VERSION "10.8"

NS_ :

BS_:

BU_:
VAL_TABLE_ Value_Table_Track_Status 7 "New Coasting Target" 6 "Invalid Coasting Target" 5 "Merged Target" 4 "Coasting Target" 3 "Updated Target" 2 "New Updated Target" 1 "New Target" 0 "No Target" ;

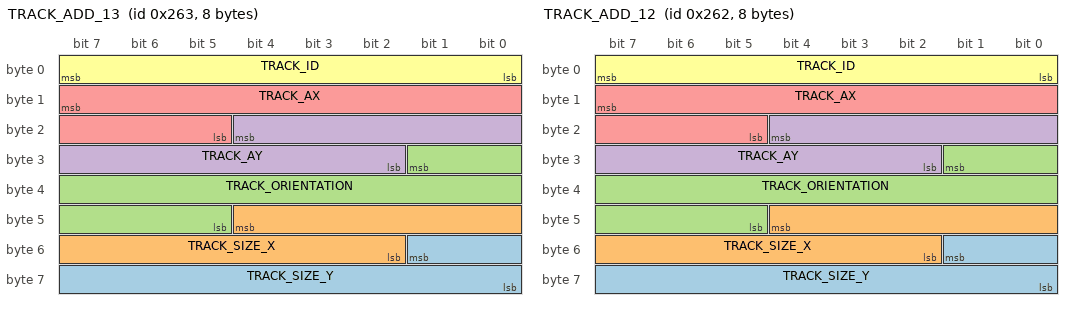
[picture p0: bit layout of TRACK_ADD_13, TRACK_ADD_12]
BO_ 611 TRACK_ADD_13: 8 Vector__XXX
 SG_ TRACK_SIZE_Y : 49|10@0+ (0.01,0) [0|10.23] "m" Vector__XXX
 SG_ TRACK_SIZE_X : 44|11@0+ (0.01,0) [0|20.47] "m" Vector__XXX
 SG_ TRACK_ORIENTATION : 25|13@0- (0.002,0) [-8.192|8.19] "rad" Vector__XXX
 SG_ TRACK_AY : 20|11@0- (0.01,0) [-10.24|10.23] "m/s^2" Vector__XXX
 SG_ TRACK_AX : 15|11@0- (0.01,0) [-10.24|10.23] "m/s^2" Vector__XXX
 SG_ TRACK_ID : 7|8@0+ (1,0) [0|255] "" Vector__XXX

BO_ 610 TRACK_ADD_12: 8 Vector__XXX
 SG_ TRACK_SIZE_Y : 49|10@0+ (0.01,0) [0|10.23] "m" Vector__XXX
 SG_ TRACK_SIZE_X : 44|11@0+ (0.01,0) [0|20.47] "m" Vector__XXX
 SG_ TRACK_ORIENTATION : 25|13@0- (0.002,0) [-8.192|8.19] "rad" Vector__XXX
 SG_ TRACK_AY : 20|11@0- (0.01,0) [-10.24|10.23] "m/s^2" Vector__XXX
 SG_ TRACK_AX : 15|11@0- (0.01,0) [-10.24|10.23] "m/s^2" Vector__XXX
 SG_ TRACK_ID : 7|8@0+ (1,0) [0|255] "" Vector__XXX

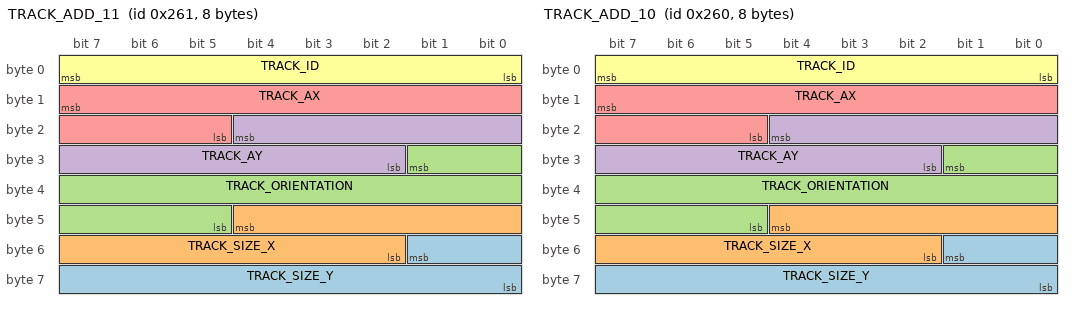
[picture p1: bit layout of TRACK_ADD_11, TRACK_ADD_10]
BO_ 609 TRACK_ADD_11: 8 Vector__XXX
 SG_ TRACK_SIZE_Y : 49|10@0+ (0.01,0) [0|10.23] "m" Vector__XXX
 SG_ TRACK_SIZE_X : 44|11@0+ (0.01,0) [0|20.47] "m" Vector__XXX
 SG_ TRACK_ORIENTATION : 25|13@0- (0.002,0) [-8.192|8.19] "rad" Vector__XXX
 SG_ TRACK_AY : 20|11@0- (0.01,0) [-10.24|10.23] "m/s^2" Vector__XXX
 SG_ TRACK_AX : 15|11@0- (0.01,0) [-10.24|10.23] "m/s^2" Vector__XXX
 SG_ TRACK_ID : 7|8@0+ (1,0) [0|255] "" Vector__XXX

BO_ 608 TRACK_ADD_10: 8 Vector__XXX
 SG_ TRACK_SIZE_Y : 49|10@0+ (0.01,0) [0|10.23] "m" Vector__XXX
 SG_ TRACK_SIZE_X : 44|11@0+ (0.01,0) [0|20.47] "m" Vector__XXX
 SG_ TRACK_ORIENTATION : 25|13@0- (0.002,0) [-8.192|8.19] "rad" Vector__XXX
 SG_ TRACK_AY : 20|11@0- (0.01,0) [-10.24|10.23] "m/s^2" Vector__XXX
 SG_ TRACK_AX : 15|11@0- (0.01,0) [-10.24|10.23] "m/s^2" Vector__XXX
 SG_ TRACK_ID : 7|8@0+ (1,0) [0|255] "" Vector__XXX

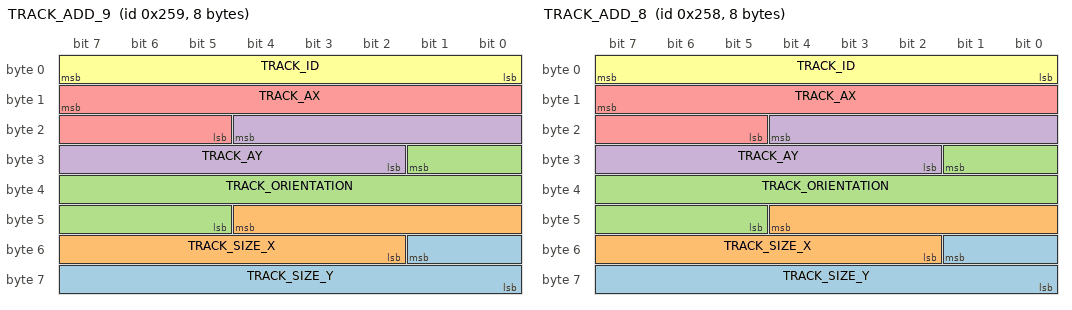
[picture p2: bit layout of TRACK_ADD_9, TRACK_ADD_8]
BO_ 601 TRACK_ADD_9: 8 Vector__XXX
 SG_ TRACK_SIZE_Y : 49|10@0+ (0.01,0) [0|10.23] "m" Vector__XXX
 SG_ TRACK_SIZE_X : 44|11@0+ (0.01,0) [0|20.47] "m" Vector__XXX
 SG_ TRACK_ORIENTATION : 25|13@0- (0.002,0) [-8.192|8.19] "rad" Vector__XXX
 SG_ TRACK_AY : 20|11@0- (0.01,0) [-10.24|10.23] "m/s^2" Vector__XXX
 SG_ TRACK_AX : 15|11@0- (0.01,0) [-10.24|10.23] "m/s^2" Vector__XXX
 SG_ TRACK_ID : 7|8@0+ (1,0) [0|255] "" Vector__XXX

BO_ 600 TRACK_ADD_8: 8 Vector__XXX
 SG_ TRACK_SIZE_Y : 49|10@0+ (0.01,0) [0|10.23] "m" Vector__XXX
 SG_ TRACK_SIZE_X : 44|11@0+ (0.01,0) [0|20.47] "m" Vector__XXX
 SG_ TRACK_ORIENTATION : 25|13@0- (0.002,0) [-8.192|8.19] "rad" Vector__XXX
 SG_ TRACK_AY : 20|11@0- (0.01,0) [-10.24|10.23] "m/s^2" Vector__XXX
 SG_ TRACK_AX : 15|11@0- (0.01,0) [-10.24|10.23] "m/s^2" Vector__XXX
 SG_ TRACK_ID : 7|8@0+ (1,0) [0|255] "" Vector__XXX

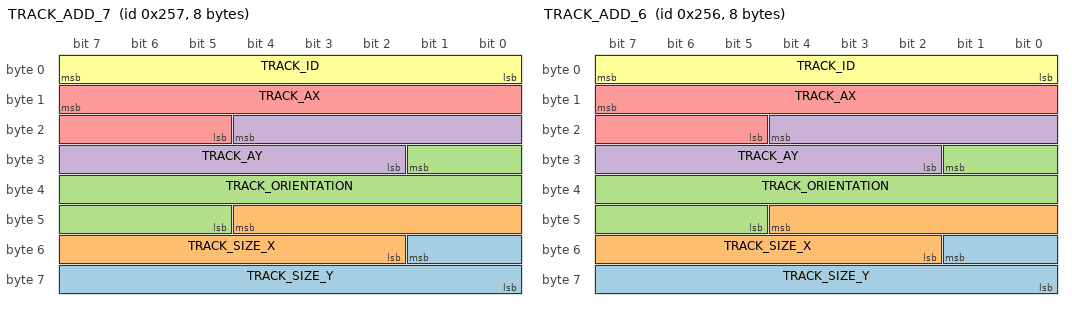
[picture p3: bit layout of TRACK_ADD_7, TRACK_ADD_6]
BO_ 599 TRACK_ADD_7: 8 Vector__XXX
 SG_ TRACK_SIZE_Y : 49|10@0+ (0.01,0) [0|10.23] "m" Vector__XXX
 SG_ TRACK_SIZE_X : 44|11@0+ (0.01,0) [0|20.47] "m" Vector__XXX
 SG_ TRACK_ORIENTATION : 25|13@0- (0.002,0) [-8.192|8.19] "rad" Vector__XXX
 SG_ TRACK_AY : 20|11@0- (0.01,0) [-10.24|10.23] "m/s^2" Vector__XXX
 SG_ TRACK_AX : 15|11@0- (0.01,0) [-10.24|10.23] "m/s^2" Vector__XXX
 SG_ TRACK_ID : 7|8@0+ (1,0) [0|255] "" Vector__XXX

BO_ 598 TRACK_ADD_6: 8 Vector__XXX
 SG_ TRACK_SIZE_Y : 49|10@0+ (0.01,0) [0|10.23] "m" Vector__XXX
 SG_ TRACK_SIZE_X : 44|11@0+ (0.01,0) [0|20.47] "m" Vector__XXX
 SG_ TRACK_ORIENTATION : 25|13@0- (0.002,0) [-8.192|8.19] "rad" Vector__XXX
 SG_ TRACK_AY : 20|11@0- (0.01,0) [-10.24|10.23] "m/s^2" Vector__XXX
 SG_ TRACK_AX : 15|11@0- (0.01,0) [-10.24|10.23] "m/s^2" Vector__XXX
 SG_ TRACK_ID : 7|8@0+ (1,0) [0|255] "" Vector__XXX

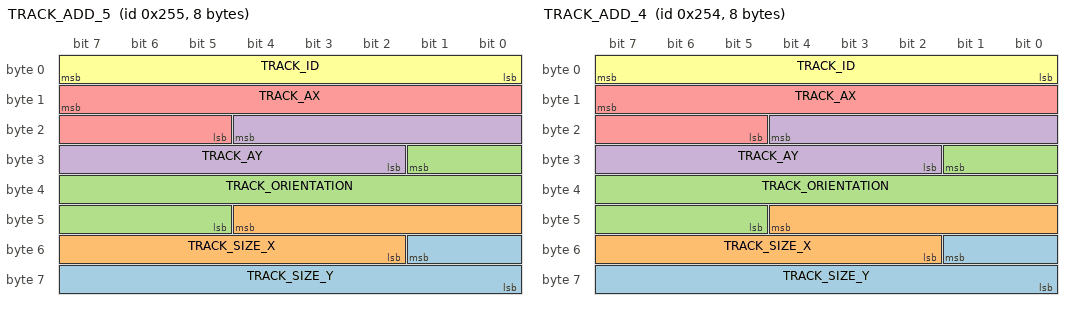
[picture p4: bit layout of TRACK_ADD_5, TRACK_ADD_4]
BO_ 597 TRACK_ADD_5: 8 Vector__XXX
 SG_ TRACK_SIZE_Y : 49|10@0+ (0.01,0) [0|10.23] "m" Vector__XXX
 SG_ TRACK_SIZE_X : 44|11@0+ (0.01,0) [0|20.47] "m" Vector__XXX
 SG_ TRACK_ORIENTATION : 25|13@0- (0.002,0) [-8.192|8.19] "rad" Vector__XXX
 SG_ TRACK_AY : 20|11@0- (0.01,0) [-10.24|10.23] "m/s^2" Vector__XXX
 SG_ TRACK_AX : 15|11@0- (0.01,0) [-10.24|10.23] "m/s^2" Vector__XXX
 SG_ TRACK_ID : 7|8@0+ (1,0) [0|255] "" Vector__XXX

BO_ 596 TRACK_ADD_4: 8 Vector__XXX
 SG_ TRACK_SIZE_Y : 49|10@0+ (0.01,0) [0|10.23] "m" Vector__XXX
 SG_ TRACK_SIZE_X : 44|11@0+ (0.01,0) [0|20.47] "m" Vector__XXX
 SG_ TRACK_ORIENTATION : 25|13@0- (0.002,0) [-8.192|8.19] "rad" Vector__XXX
 SG_ TRACK_AY : 20|11@0- (0.01,0) [-10.24|10.23] "m/s^2" Vector__XXX
 SG_ TRACK_AX : 15|11@0- (0.01,0) [-10.24|10.23] "m/s^2" Vector__XXX
 SG_ TRACK_ID : 7|8@0+ (1,0) [0|255] "" Vector__XXX

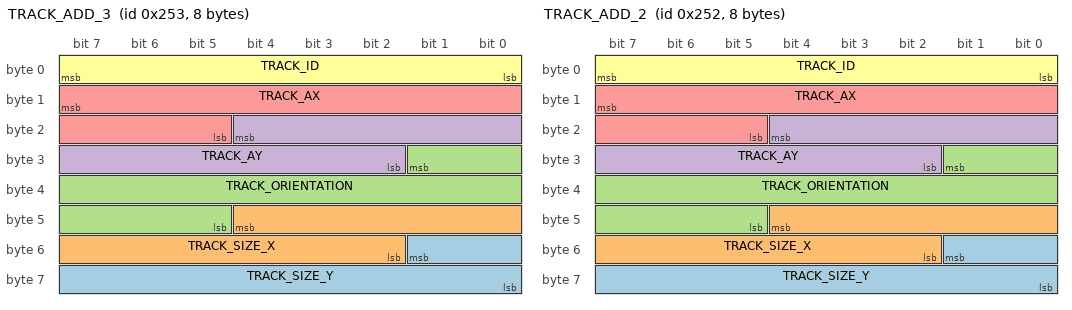
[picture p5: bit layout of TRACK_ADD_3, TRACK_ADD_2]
BO_ 595 TRACK_ADD_3: 8 Vector__XXX
 SG_ TRACK_SIZE_Y : 49|10@0+ (0.01,0) [0|10.23] "m" Vector__XXX
 SG_ TRACK_SIZE_X : 44|11@0+ (0.01,0) [0|20.47] "m" Vector__XXX
 SG_ TRACK_ORIENTATION : 25|13@0- (0.002,0) [-8.192|8.19] "rad" Vector__XXX
 SG_ TRACK_AY : 20|11@0- (0.01,0) [-10.24|10.23] "m/s^2" Vector__XXX
 SG_ TRACK_AX : 15|11@0- (0.01,0) [-10.24|10.23] "m/s^2" Vector__XXX
 SG_ TRACK_ID : 7|8@0+ (1,0) [0|255] "" Vector__XXX

BO_ 594 TRACK_ADD_2: 8 Vector__XXX
 SG_ TRACK_SIZE_Y : 49|10@0+ (0.01,0) [0|10.23] "m" Vector__XXX
 SG_ TRACK_SIZE_X : 44|11@0+ (0.01,0) [0|20.47] "m" Vector__XXX
 SG_ TRACK_ORIENTATION : 25|13@0- (0.002,0) [-8.192|8.19] "rad" Vector__XXX
 SG_ TRACK_AY : 20|11@0- (0.01,0) [-10.24|10.23] "m/s^2" Vector__XXX
 SG_ TRACK_AX : 15|11@0- (0.01,0) [-10.24|10.23] "m/s^2" Vector__XXX
 SG_ TRACK_ID : 7|8@0+ (1,0) [0|255] "" Vector__XXX

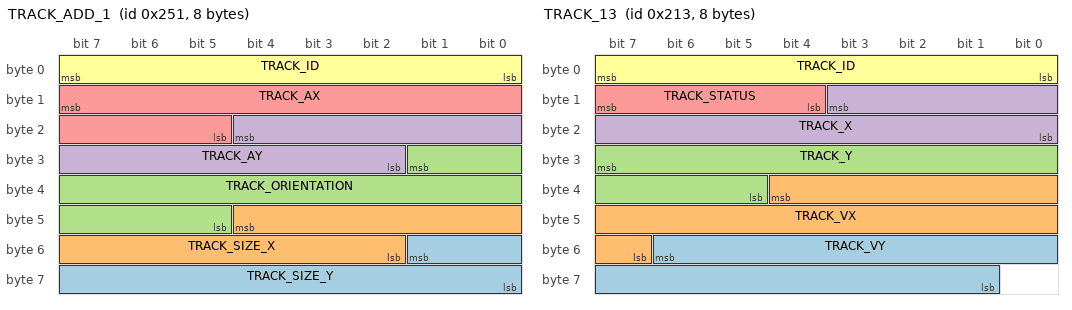
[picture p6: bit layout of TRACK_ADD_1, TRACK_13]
BO_ 593 TRACK_ADD_1: 8 Vector__XXX
 SG_ TRACK_SIZE_Y : 49|10@0+ (0.01,0) [0|10.23] "m" Vector__XXX
 SG_ TRACK_SIZE_X : 44|11@0+ (0.01,0) [0|20.47] "m" Vector__XXX
 SG_ TRACK_ORIENTATION : 25|13@0- (0.002,0) [-8.192|8.19] "rad" Vector__XXX
 SG_ TRACK_AY : 20|11@0- (0.01,0) [-10.24|10.23] "m/s^2" Vector__XXX
 SG_ TRACK_AX : 15|11@0- (0.01,0) [-10.24|10.23] "m/s^2" Vector__XXX
 SG_ TRACK_ID : 7|8@0+ (1,0) [0|255] "" Vector__XXX

BO_ 531 TRACK_13: 8 Vector__XXX
 SG_ TRACK_VY : 54|14@0- (0.01,0) [-81.92|81.91] "m/s" Vector__XXX
 SG_ TRACK_VX : 36|14@0- (0.01,0) [-81.92|81.91] "m/s" Vector__XXX
 SG_ TRACK_Y : 31|11@0- (0.04,0) [-40.9|40.9] "m" Vector__XXX
 SG_ TRACK_X : 11|12@0- (0.1,0) [-204.8|204.7] "m" Vector__XXX
 SG_ TRACK_STATUS : 15|4@0+ (1,0) [0|0] "" Vector__XXX
 SG_ TRACK_ID : 7|8@0+ (1,0) [0|255] "" Vector__XXX

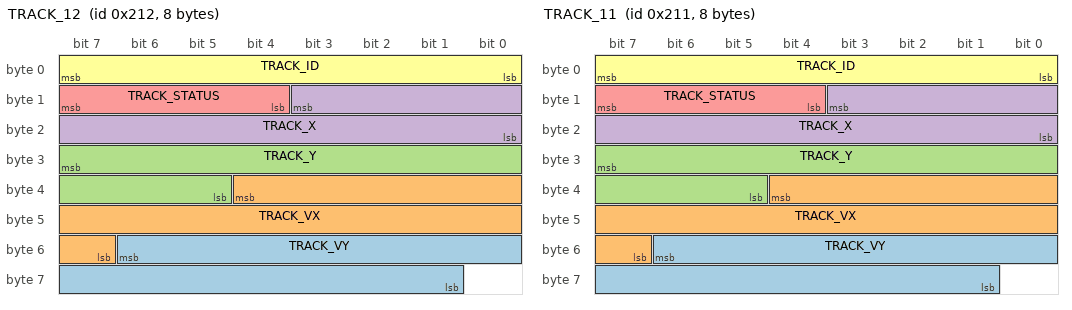
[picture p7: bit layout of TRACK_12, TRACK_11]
BO_ 530 TRACK_12: 8 Vector__XXX
 SG_ TRACK_VY : 54|14@0- (0.01,0) [-81.92|81.91] "m/s" Vector__XXX
 SG_ TRACK_VX : 36|14@0- (0.01,0) [-81.92|81.91] "m/s" Vector__XXX
 SG_ TRACK_Y : 31|11@0- (0.04,0) [-40.9|40.9] "m" Vector__XXX
 SG_ TRACK_X : 11|12@0- (0.1,0) [-204.8|204.7] "m" Vector__XXX
 SG_ TRACK_STATUS : 15|4@0+ (1,0) [0|0] "" Vector__XXX
 SG_ TRACK_ID : 7|8@0+ (1,0) [0|255] "" Vector__XXX

BO_ 529 TRACK_11: 8 Vector__XXX
 SG_ TRACK_VY : 54|14@0- (0.01,0) [-81.92|81.91] "m/s" Vector__XXX
 SG_ TRACK_VX : 36|14@0- (0.01,0) [-81.92|81.91] "m/s" Vector__XXX
 SG_ TRACK_Y : 31|11@0- (0.04,0) [-40.9|40.9] "m" Vector__XXX
 SG_ TRACK_X : 11|12@0- (0.1,0) [-204.8|204.7] "m" Vector__XXX
 SG_ TRACK_STATUS : 15|4@0+ (1,0) [0|0] "" Vector__XXX
 SG_ TRACK_ID : 7|8@0+ (1,0) [0|255] "" Vector__XXX

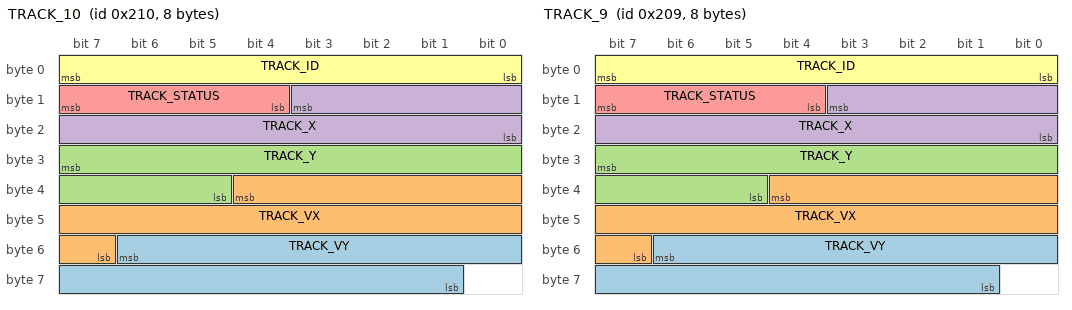
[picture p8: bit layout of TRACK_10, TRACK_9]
BO_ 528 TRACK_10: 8 Vector__XXX
 SG_ TRACK_VY : 54|14@0- (0.01,0) [-81.92|81.91] "m/s" Vector__XXX
 SG_ TRACK_VX : 36|14@0- (0.01,0) [-81.92|81.91] "m/s" Vector__XXX
 SG_ TRACK_Y : 31|11@0- (0.04,0) [-40.9|40.9] "m" Vector__XXX
 SG_ TRACK_X : 11|12@0- (0.1,0) [-204.8|204.7] "m" Vector__XXX
 SG_ TRACK_STATUS : 15|4@0+ (1,0) [0|0] "" Vector__XXX
 SG_ TRACK_ID : 7|8@0+ (1,0) [0|255] "" Vector__XXX

BO_ 521 TRACK_9: 8 Vector__XXX
 SG_ TRACK_VY : 54|14@0- (0.01,0) [-81.92|81.91] "m/s" Vector__XXX
 SG_ TRACK_VX : 36|14@0- (0.01,0) [-81.92|81.91] "m/s" Vector__XXX
 SG_ TRACK_Y : 31|11@0- (0.04,0) [-40.9|40.9] "m" Vector__XXX
 SG_ TRACK_X : 11|12@0- (0.1,0) [-204.8|204.7] "m" Vector__XXX
 SG_ TRACK_STATUS : 15|4@0+ (1,0) [0|0] "" Vector__XXX
 SG_ TRACK_ID : 7|8@0+ (1,0) [0|255] "" Vector__XXX

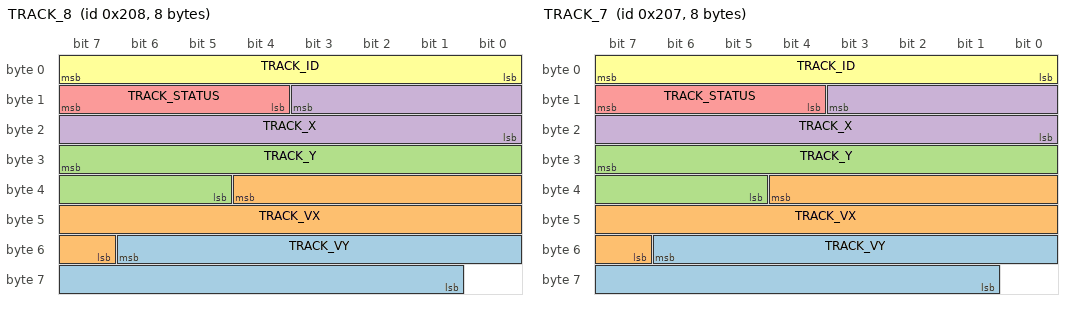
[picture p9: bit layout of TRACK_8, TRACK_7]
BO_ 520 TRACK_8: 8 Vector__XXX
 SG_ TRACK_VY : 54|14@0- (0.01,0) [-81.92|81.91] "m/s" Vector__XXX
 SG_ TRACK_VX : 36|14@0- (0.01,0) [-81.92|81.91] "m/s" Vector__XXX
 SG_ TRACK_Y : 31|11@0- (0.04,0) [-40.9|40.9] "m" Vector__XXX
 SG_ TRACK_X : 11|12@0- (0.1,0) [-204.8|204.7] "m" Vector__XXX
 SG_ TRACK_STATUS : 15|4@0+ (1,0) [0|0] "" Vector__XXX
 SG_ TRACK_ID : 7|8@0+ (1,0) [0|255] "" Vector__XXX

BO_ 519 TRACK_7: 8 Vector__XXX
 SG_ TRACK_VY : 54|14@0- (0.01,0) [-81.92|81.91] "m/s" Vector__XXX
 SG_ TRACK_VX : 36|14@0- (0.01,0) [-81.92|81.91] "m/s" Vector__XXX
 SG_ TRACK_Y : 31|11@0- (0.04,0) [-40.9|40.9] "m" Vector__XXX
 SG_ TRACK_X : 11|12@0- (0.1,0) [-204.8|204.7] "m" Vector__XXX
 SG_ TRACK_STATUS : 15|4@0+ (1,0) [0|0] "" Vector__XXX
 SG_ TRACK_ID : 7|8@0+ (1,0) [0|255] "" Vector__XXX

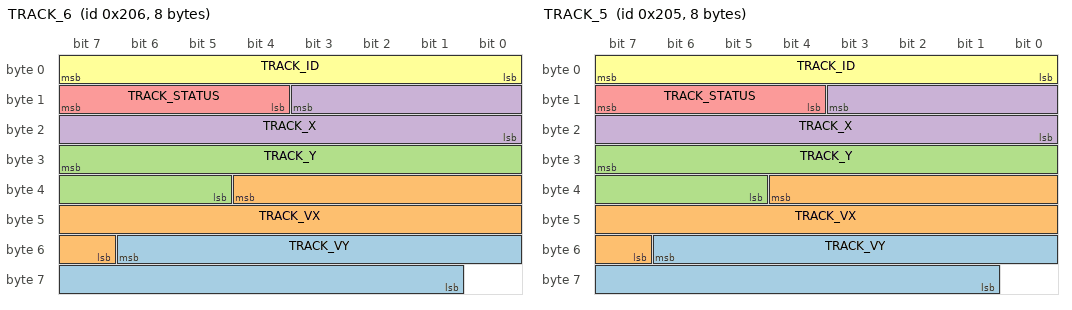
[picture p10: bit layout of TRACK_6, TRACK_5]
BO_ 518 TRACK_6: 8 Vector__XXX
 SG_ TRACK_VY : 54|14@0- (0.01,0) [-81.92|81.91] "m/s" Vector__XXX
 SG_ TRACK_VX : 36|14@0- (0.01,0) [-81.92|81.91] "m/s" Vector__XXX
 SG_ TRACK_Y : 31|11@0- (0.04,0) [-40.9|40.9] "m" Vector__XXX
 SG_ TRACK_X : 11|12@0- (0.1,0) [-204.8|204.7] "m" Vector__XXX
 SG_ TRACK_STATUS : 15|4@0+ (1,0) [0|0] "" Vector__XXX
 SG_ TRACK_ID : 7|8@0+ (1,0) [0|255] "" Vector__XXX

BO_ 517 TRACK_5: 8 Vector__XXX
 SG_ TRACK_VY : 54|14@0- (0.01,0) [-81.92|81.91] "m/s" Vector__XXX
 SG_ TRACK_VX : 36|14@0- (0.01,0) [-81.92|81.91] "m/s" Vector__XXX
 SG_ TRACK_Y : 31|11@0- (0.04,0) [-40.9|40.9] "m" Vector__XXX
 SG_ TRACK_X : 11|12@0- (0.1,0) [-204.8|204.7] "m" Vector__XXX
 SG_ TRACK_STATUS : 15|4@0+ (1,0) [0|0] "" Vector__XXX
 SG_ TRACK_ID : 7|8@0+ (1,0) [0|255] "" Vector__XXX

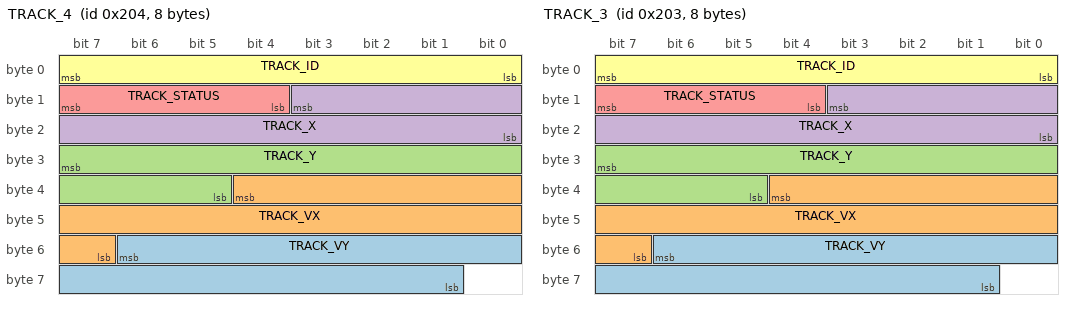
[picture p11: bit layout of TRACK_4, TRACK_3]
BO_ 516 TRACK_4: 8 Vector__XXX
 SG_ TRACK_VY : 54|14@0- (0.01,0) [-81.92|81.91] "m/s" Vector__XXX
 SG_ TRACK_VX : 36|14@0- (0.01,0) [-81.92|81.91] "m/s" Vector__XXX
 SG_ TRACK_Y : 31|11@0- (0.04,0) [-40.9|40.9] "m" Vector__XXX
 SG_ TRACK_X : 11|12@0- (0.1,0) [-204.8|204.7] "m" Vector__XXX
 SG_ TRACK_STATUS : 15|4@0+ (1,0) [0|0] "" Vector__XXX
 SG_ TRACK_ID : 7|8@0+ (1,0) [0|255] "" Vector__XXX

BO_ 515 TRACK_3: 8 Vector__XXX
 SG_ TRACK_VY : 54|14@0- (0.01,0) [-81.92|81.91] "m/s" Vector__XXX
 SG_ TRACK_VX : 36|14@0- (0.01,0) [-81.92|81.91] "m/s" Vector__XXX
 SG_ TRACK_Y : 31|11@0- (0.04,0) [-40.9|40.9] "m" Vector__XXX
 SG_ TRACK_X : 11|12@0- (0.1,0) [-204.8|204.7] "m" Vector__XXX
 SG_ TRACK_STATUS : 15|4@0+ (1,0) [0|0] "" Vector__XXX
 SG_ TRACK_ID : 7|8@0+ (1,0) [0|255] "" Vector__XXX

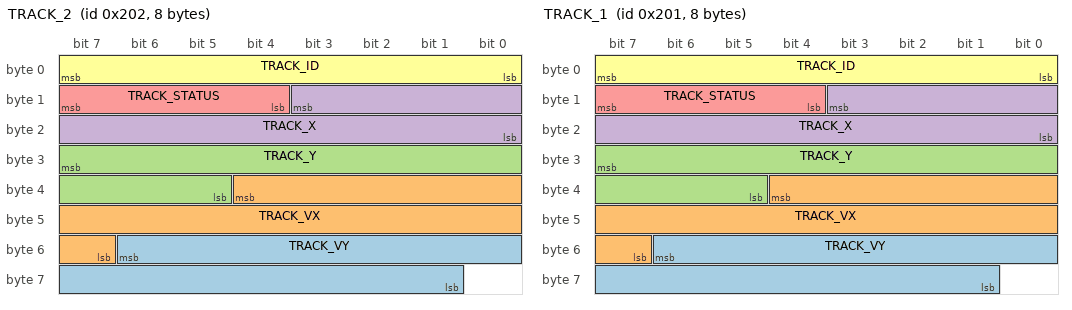
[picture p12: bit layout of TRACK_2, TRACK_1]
BO_ 514 TRACK_2: 8 Vector__XXX
 SG_ TRACK_VY : 54|14@0- (0.01,0) [-81.92|81.91] "m/s" Vector__XXX
 SG_ TRACK_VX : 36|14@0- (0.01,0) [-81.92|81.91] "m/s" Vector__XXX
 SG_ TRACK_Y : 31|11@0- (0.04,0) [-40.9|40.9] "m" Vector__XXX
 SG_ TRACK_X : 11|12@0- (0.1,0) [-204.8|204.7] "m" Vector__XXX
 SG_ TRACK_STATUS : 15|4@0+ (1,0) [0|0] "" Vector__XXX
 SG_ TRACK_ID : 7|8@0+ (1,0) [0|255] "" Vector__XXX

BO_ 513 TRACK_1: 8 Vector__XXX
 SG_ TRACK_VY : 54|14@0- (0.01,0) [-81.92|81.91] "m/s" Vector__XXX
 SG_ TRACK_VX : 36|14@0- (0.01,0) [-81.92|81.91] "m/s" Vector__XXX
 SG_ TRACK_Y : 31|11@0- (0.04,0) [-40.9|40.9] "m" Vector__XXX
 SG_ TRACK_X : 11|12@0- (0.1,0) [-204.8|204.7] "m" Vector__XXX
 SG_ TRACK_STATUS : 15|4@0+ (1,0) [0|0] "" Vector__XXX
 SG_ TRACK_ID : 7|8@0+ (1,0) [0|255] "" Vector__XXX

BO_ 647 from_control_team: 8 Vector__XXX
 SG_ lane_change_info : 8|2@1+ (1,0) [0|3] "" Vector__XXX
 SG_ speed_limit : 0|8@1+ (1,0) [0|120] "kph" Vector__XXX

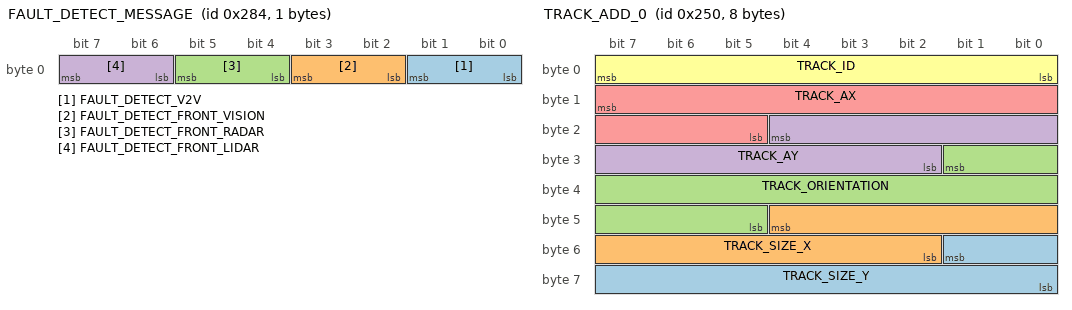
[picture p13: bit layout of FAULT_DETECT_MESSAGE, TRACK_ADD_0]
BO_ 644 FAULT_DETECT_MESSAGE: 1 Vector__XXX
 SG_ FAULT_DETECT_V2V : 1|2@0+ (1,0) [0|0] "" Vector__XXX
 SG_ FAULT_DETECT_FRONT_VISION : 3|2@0+ (1,0) [0|0] "" Vector__XXX
 SG_ FAULT_DETECT_FRONT_RADAR : 5|2@0+ (1,0) [0|0] "" Vector__XXX
 SG_ FAULT_DETECT_FRONT_LIDAR : 7|2@0+ (1,0) [0|0] "" Vector__XXX

BO_ 592 TRACK_ADD_0: 8 Vector__XXX
 SG_ TRACK_SIZE_Y : 49|10@0+ (0.01,0) [0|10.23] "m" Vector__XXX
 SG_ TRACK_SIZE_X : 44|11@0+ (0.01,0) [0|20.47] "m" Vector__XXX
 SG_ TRACK_ORIENTATION : 25|13@0- (0.002,0) [-8.192|8.19] "rad" Vector__XXX
 SG_ TRACK_AY : 20|11@0- (0.01,0) [-10.24|10.23] "m/s^2" Vector__XXX
 SG_ TRACK_AX : 15|11@0- (0.01,0) [-10.24|10.23] "m/s^2" Vector__XXX
 SG_ TRACK_ID : 7|8@0+ (1,0) [0|255] "" Vector__XXX

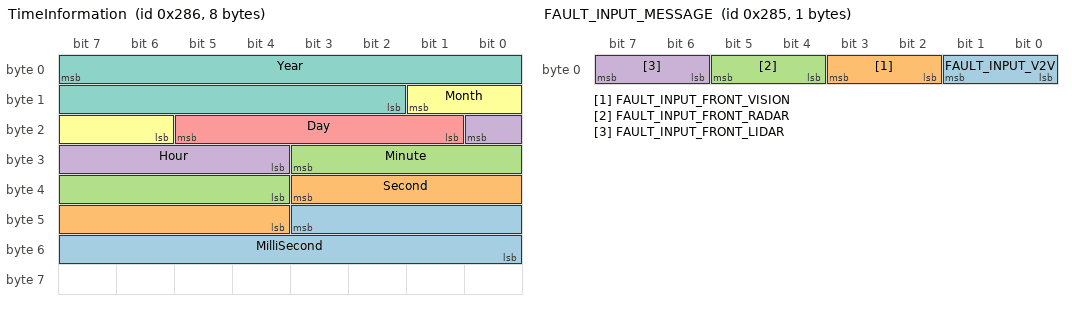
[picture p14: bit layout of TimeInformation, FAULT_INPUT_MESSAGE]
BO_ 646 TimeInformation: 8 Vector__XXX
 SG_ MilliSecond : 43|12@0+ (1,0) [0|0] "" Vector__XXX
 SG_ Second : 35|8@0+ (1,0) [0|0] "" Vector__XXX
 SG_ Minute : 27|8@0+ (1,0) [0|0] "" Vector__XXX
 SG_ Hour : 16|5@0+ (1,0) [0|0] "" Vector__XXX
 SG_ Day : 21|5@0+ (1,0) [0|0] "" Vector__XXX
 SG_ Month : 9|4@0+ (1,0) [0|0] "" Vector__XXX
 SG_ Year : 7|14@0+ (1,0) [0|0] "" Vector__XXX

BO_ 645 FAULT_INPUT_MESSAGE: 1 Vector__XXX
 SG_ FAULT_INPUT_V2V : 1|2@0+ (1,0) [0|0] "" Vector__XXX
 SG_ FAULT_INPUT_FRONT_VISION : 3|2@0+ (1,0) [0|0] "" Vector__XXX
 SG_ FAULT_INPUT_FRONT_RADAR : 5|2@0+ (1,0) [0|0] "" Vector__XXX
 SG_ FAULT_INPUT_FRONT_LIDAR : 7|2@0+ (1,0) [0|0] "" Vector__XXX

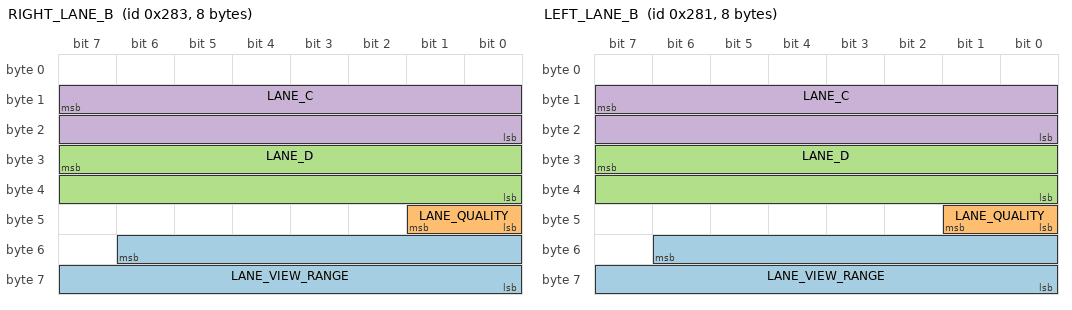
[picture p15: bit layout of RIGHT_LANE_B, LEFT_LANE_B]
BO_ 643 RIGHT_LANE_B: 8 Vector__XXX
 SG_ LANE_VIEW_RANGE : 54|15@0+ (0.00390625,0) [0|0] "" Vector__XXX
 SG_ LANE_QUALITY : 41|2@0+ (1,0) [0|0] "" Vector__XXX
 SG_ LANE_D : 31|16@0- (0.00390625,0) [0|0] "" Vector__XXX
 SG_ LANE_C : 15|16@0+ (1.52588E-005,-0.5) [0|0] "" Vector__XXX

BO_ 642 RIGHT_LANE_A: 8 Vector__XXX
 SG_ LANE_B : 39|32@0+ (2.3283064E-010,-0.5) [0|0] "1/Meters" Vector__XXX
 SG_ LANE_A : 7|32@0+ (1.45519E-011,-0.03125) [0|0] "1/Meters^2" Vector__XXX

BO_ 641 LEFT_LANE_B: 8 Vector__XXX
 SG_ LANE_VIEW_RANGE : 54|15@0+ (0.00390625,0) [0|0] "" Vector__XXX
 SG_ LANE_QUALITY : 41|2@0+ (1,0) [0|0] "" Vector__XXX
 SG_ LANE_D : 31|16@0- (0.00390625,0) [0|0] "" Vector__XXX
 SG_ LANE_C : 15|16@0+ (1.52588E-005,-0.5) [0|0] "" Vector__XXX

BO_ 640 LEFT_LANE_A: 8 Vector__XXX
 SG_ LANE_B : 39|32@0+ (2.3283064E-010,-0.5) [0|0] "1/Meters" Vector__XXX
 SG_ LANE_A : 7|32@0+ (1.45519E-011,-0.03125) [0|0] "1/Meters^2" Vector__XXX

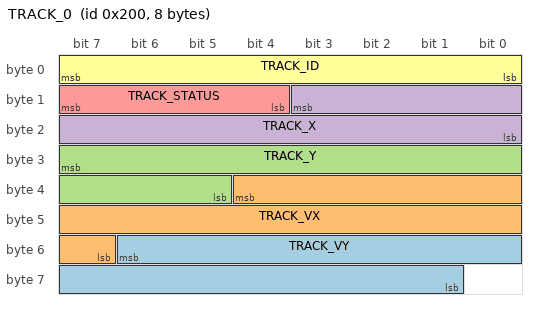
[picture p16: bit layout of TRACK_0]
BO_ 512 TRACK_0: 8 Vector__XXX
 SG_ TRACK_VY : 54|14@0- (0.01,0) [-81.92|81.91] "m/s" Vector__XXX
 SG_ TRACK_VX : 36|14@0- (0.01,0) [-81.92|81.91] "m/s" Vector__XXX
 SG_ TRACK_Y : 31|11@0- (0.04,0) [-40.9|40.9] "m" Vector__XXX
 SG_ TRACK_X : 11|12@0- (0.1,0) [-204.8|204.7] "m" Vector__XXX
 SG_ TRACK_STATUS : 15|4@0+ (1,0) [0|0] "" Vector__XXX
 SG_ TRACK_ID : 7|8@0+ (1,0) [0|255] "" Vector__XXX

BA_DEF_ SG_  "GenSigSendType" ENUM  "Cyclic","OnWrite","OnWriteWithRepetition","OnChange","OnChangeWithRepetition","IfActive","IfActiveWithRepetition","NoSigSendType";
BA_DEF_ BO_  "GenMsgILSupport" ENUM  "No","Yes";
BA_DEF_ BO_  "GenMsgCycleTime" INT 2 50000;
BA_DEF_ BO_  "GenMsgDelayTime" INT 1 1000;
BA_DEF_ BO_  "GenMsgNrOfRepetitions" INT 1 999999;
BA_DEF_ BO_  "GenMsgSendType" ENUM  "Cyclic","not_used","not_used","not_used","not_used","not_used","not_used","IfActive","NoMsgSendType";
BA_DEF_ BU_  "ILUsed" ENUM  "No","Yes";
BA_DEF_  "DBName" STRING ;
BA_DEF_  "Baudrate" INT 50000 1000000;
BA_DEF_  "BusType" STRING ;
BA_DEF_  "Manufacturer" STRING ;
BA_DEF_REL_ BU_SG_REL_  "GenSigTimeoutTime" INT 0 5000;
BA_DEF_DEF_  "GenSigSendType" "Cyclic";
BA_DEF_DEF_  "GenMsgILSupport" "Yes";
BA_DEF_DEF_  "GenMsgCycleTime" 50;
BA_DEF_DEF_  "GenMsgDelayTime" 10;
BA_DEF_DEF_  "GenMsgNrOfRepetitions" 3;
BA_DEF_DEF_  "GenMsgSendType" "Cyclic";
BA_DEF_DEF_  "ILUsed" "Yes";
BA_DEF_DEF_  "DBName" "";
BA_DEF_DEF_  "Baudrate" 500000;
BA_DEF_DEF_  "BusType" "CAN";
BA_DEF_DEF_  "Manufacturer" "Geely";
BA_DEF_DEF_REL_ "GenSigTimeoutTime" 500;
BA_ "DBName" "SENSOR_FUSION_revised";
